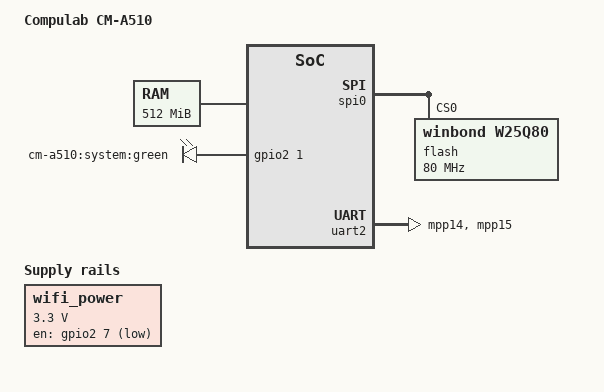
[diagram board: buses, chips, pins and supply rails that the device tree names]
#include "dove.dtsi"
/ {
	model = "Compulab CM-A510";
	compatible = "compulab,cm-a510", "marvell,dove";
	memory {
		device_type = "memory";
		reg = <0x00000000 0x20000000>;
	};
	leds {
		compatible = "gpio-leds";
		pinctrl-0 = <&pmx_nand_gpo>;
		pinctrl-names = "default";
		led-system {
			label = "cm-a510:system:green";
			gpios = <&gpio2 1 GPIO_ACTIVE_HIGH>;
			default-state = "keep";
		};
	};
	wifi_power: regulator-1 {
		compatible = "regulator-fixed";
		regulator-name = "WiFi Power";
		regulator-min-microvolt = <3300000>;
		regulator-max-microvolt = <3300000>;
		gpio = <&gpio2 7 GPIO_ACTIVE_HIGH>;
	};
};
&mdio {
	ethphy: ethernet-phy@3 {
		reg = <3>;
		status = "disabled";
	};
};
&eth {
	ethernet-port@0 {
		phy-handle = <&ethphy>;
	};
};
&i2c0 {
	opt_audio: audio@1a {
		compatible = "ti,tlv320aic23";
		reg = <0x1a>;
		status = "disabled";
	};
};
&pcie { status = "disabled"; };
&pcie1 {
	pinctrl-0 = <&pmx_pcie1_clkreq>;
	pinctrl-names = "default";
	status = "disabled";
};
&pinctrl {
	pmx_uart2: pmx-uart2 {
		marvell,pins = "mpp14", "mpp15";
		marvell,function = "uart2";
	};
};
&sdio1 {
	non-removable;
	vmmc-supply = <&wifi_power>;
	reset-gpio = <&gpio2 6 GPIO_ACTIVE_LOW>;
	status = "disabled";
};
&spi0 {
	status = "okay";
	flash@0 {
		compatible = "winbond,w25q80";
		spi-max-frequency = <80000000>;
		reg = <0>;
	};
};
&spi1 {
	pinctrl-0 = <&pmx_spi1_20_23>;
	pinctrl-names = "default";
	status = "disabled";
	opt_touch: touchscreen@0 {
		compatible = "ti,tsc2046";
		spi-max-frequency = <2500000>;
		reg = <0>;
		pinctrl-0 = <&pmx_gpio_13>;
		pinctrl-names = "default";
		interrupts-extended = <&gpio0 13 IRQ_TYPE_EDGE_FALLING>;
	};
};
&uart2 {
	pinctrl-0 = <&pmx_uart2>;
	pinctrl-names = "default";
};
